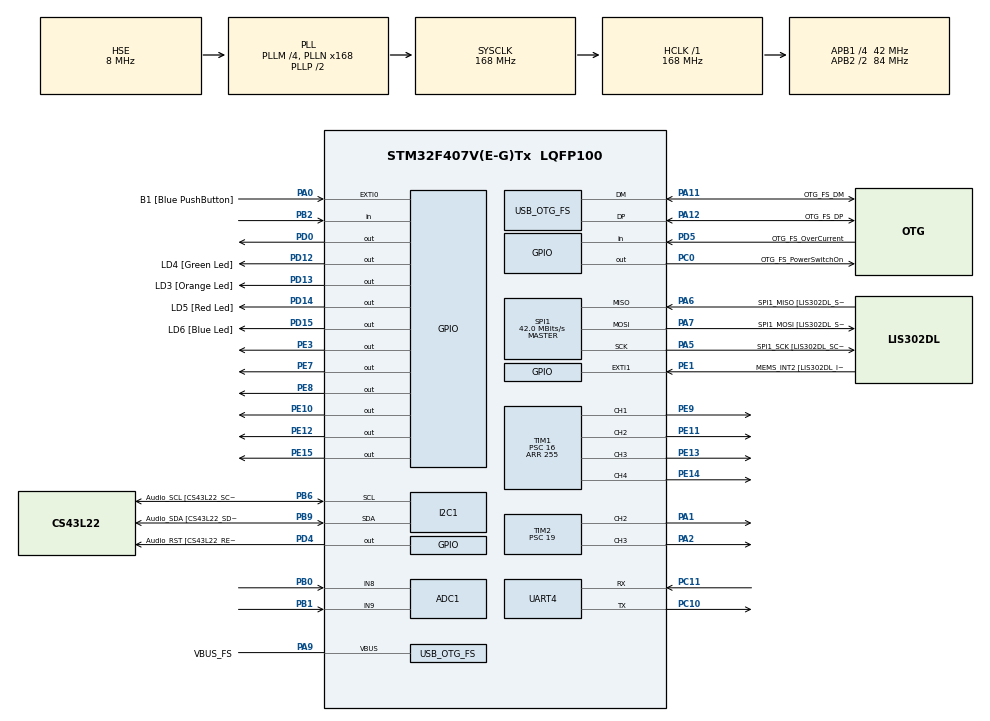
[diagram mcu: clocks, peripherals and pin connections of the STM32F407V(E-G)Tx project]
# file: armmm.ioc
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ADC1.Channel-0\#ChannelRegularConversion=ADC_CHANNEL_8
ADC1.Channel-1\#ChannelRegularConversion=ADC_CHANNEL_9
ADC1.ContinuousConvMode=ENABLE
ADC1.DMAContinuousRequests=ENABLE
ADC1.NbrOfConversion=2
ADC1.NbrOfConversionFlag=1
ADC1.Rank-0\#ChannelRegularConversion=1
ADC1.Rank-1\#ChannelRegularConversion=2
ADC1.SamplingTime-0\#ChannelRegularConversion=ADC_SAMPLETIME_3CYCLES
ADC1.SamplingTime-1\#ChannelRegularConversion=ADC_SAMPLETIME_3CYCLES
ADC1.ScanConvMode=ENABLE
ADC1.master=1
Dma.ADC1.1.Direction=DMA_PERIPH_TO_MEMORY
Dma.ADC1.1.FIFOMode=DMA_FIFOMODE_DISABLE
Dma.ADC1.1.Instance=DMA2_Stream0
Dma.ADC1.1.MemDataAlignment=DMA_MDATAALIGN_HALFWORD
Dma.ADC1.1.MemInc=DMA_MINC_ENABLE
Dma.ADC1.1.Mode=DMA_CIRCULAR
Dma.ADC1.1.PeriphDataAlignment=DMA_PDATAALIGN_HALFWORD
Dma.ADC1.1.PeriphInc=DMA_PINC_DISABLE
Dma.ADC1.1.Priority=DMA_PRIORITY_LOW
Dma.Request0=UART4_RX
Dma.Request1=ADC1
Dma.UART4_RX.0.Direction=DMA_PERIPH_TO_MEMORY
Dma.UART4_RX.0.FIFOMode=DMA_FIFOMODE_DISABLE
Dma.UART4_RX.0.Instance=DMA1_Stream2
Dma.UART4_RX.0.MemDataAlignment=DMA_MDATAALIGN_BYTE
Dma.UART4_RX.0.MemInc=DMA_MINC_ENABLE
Dma.UART4_RX.0.Mode=DMA_CIRCULAR
Dma.UART4_RX.0.PeriphDataAlignment=DMA_PDATAALIGN_BYTE
Dma.UART4_RX.0.PeriphInc=DMA_PINC_DISABLE
Dma.UART4_RX.0.Priority=DMA_PRIORITY_HIGH
FREERTOS.Tasks01=rosTask,24,512,StartRosTask,Default,NULL,Dynamic,NULL,NULL;pidTask,40,512,StartPidTask,Default,NULL,Dynamic,NULL,NULL
FREERTOS.configUSE_NEWLIB_REENTRANT=1
I2C1.I2C_Mode=I2C_Fast
Mcu.Family=STM32F4
Mcu.Name=STM32F407V(E-G)Tx
Mcu.Package=LQFP100
NVIC.DMA1_Stream2_IRQn=true\:5\:0\:false\:false\:true\:true\:false\:true\:true
NVIC.DMA2_Stream0_IRQn=true\:5\:0\:false\:false\:true\:true\:false\:true\:true
NVIC.OTG_FS_IRQn=true\:5\:0\:false\:false\:true\:true\:true\:true\:true
NVIC.PriorityGroup=NVIC_PRIORITYGROUP_4
NVIC.TIM6_DAC_IRQn=true\:15\:0\:false\:false\:true\:false\:false\:true\:true
NVIC.TimeBase=TIM6_DAC_IRQn
NVIC.TimeBaseIP=TIM6
NVIC.UART4_IRQn=true\:5\:0\:false\:false\:true\:true\:true\:true\:true
PA0-WKUP.GPIO_Label=B1 [Blue PushButton]
PA0-WKUP.GPIO_ModeDefaultEXTI=GPIO_MODE_EVT_RISING
PA0-WKUP.GPIO_PuPd=GPIO_NOPULL
PA0-WKUP.Signal=GPXTI0
PA1.Signal=S_TIM2_CH2
PA10.GPIO_Label=OTG_FS_ID
PA10.GPIO_Mode=GPIO_MODE_AF_PP
PA10.GPIO_PuPd=GPIO_NOPULL
PA10.GPIO_Speed=GPIO_SPEED_FREQ_LOW
PA10.Signal=USB_OTG_FS_ID
PA11.GPIO_Label=OTG_FS_DM
PA11.GPIO_Mode=GPIO_MODE_AF_PP
PA11.GPIO_PuPd=GPIO_NOPULL
PA11.GPIO_Speed=GPIO_SPEED_FREQ_LOW
PA11.Mode=Device_Only
PA11.Signal=USB_OTG_FS_DM
PA12.GPIO_Label=OTG_FS_DP
PA12.GPIO_Mode=GPIO_MODE_AF_PP
PA12.GPIO_PuPd=GPIO_NOPULL
PA12.GPIO_Speed=GPIO_SPEED_FREQ_LOW
PA12.Mode=Device_Only
PA12.Signal=USB_OTG_FS_DP
PA13.GPIO_Label=SWDIO
PA13.Mode=Serial_Wire
PA13.Signal=SYS_JTMS-SWDIO
PA14.GPIO_Label=SWCLK
PA14.Mode=Serial_Wire
PA14.Signal=SYS_JTCK-SWCLK
PA2.Signal=S_TIM2_CH3
PA4.GPIO_Label=I2S3_WS [CS43L22_LRCK]
PA4.GPIO_Mode=GPIO_MODE_AF_PP
PA4.GPIO_PuPd=GPIO_NOPULL
PA4.GPIO_Speed=GPIO_SPEED_FREQ_LOW
PA4.Signal=I2S3_WS
PA5.GPIO_Label=SPI1_SCK [LIS302DL_SCL/SPC]
PA5.GPIO_Mode=GPIO_MODE_AF_PP
PA5.GPIO_PuPd=GPIO_NOPULL
PA5.GPIO_Speed=GPIO_SPEED_FREQ_LOW
PA5.Mode=Full_Duplex_Master
PA5.Signal=SPI1_SCK
PA6.GPIO_Label=SPI1_MISO [LIS302DL_SDO]
PA6.GPIO_Mode=GPIO_MODE_AF_PP
PA6.GPIO_PuPd=GPIO_NOPULL
PA6.GPIO_Speed=GPIO_SPEED_FREQ_LOW
PA6.Mode=Full_Duplex_Master
PA6.Signal=SPI1_MISO
PA7.GPIO_Label=SPI1_MOSI [LIS302DL_SDA/SDI/SDO]
PA7.GPIO_Mode=GPIO_MODE_AF_PP
PA7.GPIO_PuPd=GPIO_NOPULL
PA7.GPIO_Speed=GPIO_SPEED_FREQ_LOW
PA7.Mode=Full_Duplex_Master
PA7.Signal=SPI1_MOSI
PA9.GPIO_Label=VBUS_FS
PA9.GPIO_Mode=GPIO_MODE_INPUT
PA9.GPIO_PuPd=GPIO_NOPULL
PA9.Mode=Activate_VBUS
PA9.Signal=USB_OTG_FS_VBUS
PB0.Signal=ADCx_IN8
PB1.Signal=ADCx_IN9
PB10.GPIO_Label=CLK_IN [MP45DT02_CLK]
PB10.GPIO_Mode=GPIO_MODE_AF_PP
PB10.GPIO_PuPd=GPIO_NOPULL
PB10.GPIO_Speed=GPIO_SPEED_FREQ_LOW
PB10.Signal=I2S2_CK
PB2.Signal=GPIO_Input
PB3.GPIO_Label=SWO
PB3.Signal=SYS_JTDO-SWO
PB6.GPIO_Label=Audio_SCL [CS43L22_SCL]
PB6.GPIO_Mode=GPIO_MODE_AF_OD
PB6.GPIO_Pu=GPIO_PULLUP
PB6.GPIO_PuPd=GPIO_NOPULL
PB6.GPIO_Speed=GPIO_SPEED_FREQ_LOW
PB6.Mode=I2C
PB6.Signal=I2C1_SCL
PB9.GPIO_Label=Audio_SDA [CS43L22_SDA]
PB9.GPIO_Mode=GPIO_MODE_AF_OD
PB9.GPIO_Pu=GPIO_PULLUP
PB9.GPIO_PuPd=GPIO_NOPULL
PB9.GPIO_Speed=GPIO_SPEED_FREQ_LOW
PB9.Mode=I2C
PB9.Signal=I2C1_SDA
PC0.GPIO_Label=OTG_FS_PowerSwitchOn
PC0.GPIO_PuPd=GPIO_NOPULL
PC0.GPIO_Speed=GPIO_SPEED_FREQ_LOW
PC0.PinState=GPIO_PIN_SET
PC0.Signal=GPIO_Output
PC10.Mode=Asynchronous
PC10.Signal=UART4_TX
PC11.Mode=Asynchronous
PC11.Signal=UART4_RX
PC14-OSC32_IN.GPIO_Label=PC14-OSC32_IN
PC14-OSC32_IN.Mode=LSE-External-Oscillator
PC14-OSC32_IN.Signal=RCC_OSC32_IN
PC15-OSC32_OUT.GPIO_Label=PC15-OSC32_OUT
PC15-OSC32_OUT.Mode=LSE-External-Oscillator
PC15-OSC32_OUT.Signal=RCC_OSC32_OUT
PC3.GPIO_Label=PDM_OUT [MP45DT02_DOUT]
PC3.GPIO_Mode=GPIO_MODE_AF_PP
PC3.GPIO_PuPd=GPIO_NOPULL
PC3.GPIO_Speed=GPIO_SPEED_FREQ_LOW
PC3.Signal=I2S2_SD
PC7.GPIO_Label=I2S3_MCK [CS43L22_MCLK]
PC7.GPIO_Mode=GPIO_MODE_AF_PP
PC7.GPIO_PuPd=GPIO_NOPULL
PC7.GPIO_Speed=GPIO_SPEED_FREQ_LOW
PC7.Signal=I2S3_MCK
PD0.Signal=GPIO_Output
PD12.GPIO_Label=LD4 [Green Led]
PD12.GPIO_PuPd=GPIO_NOPULL
PD12.GPIO_Speed=GPIO_SPEED_FREQ_LOW
PD12.Signal=GPIO_Output
PD13.GPIO_Label=LD3 [Orange Led]
PD13.GPIO_PuPd=GPIO_NOPULL
PD13.GPIO_Speed=GPIO_SPEED_FREQ_LOW
PD13.Signal=GPIO_Output
PD14.GPIO_Label=LD5 [Red Led]
PD14.GPIO_PuPd=GPIO_NOPULL
PD14.GPIO_Speed=GPIO_SPEED_FREQ_LOW
PD14.Signal=GPIO_Output
PD15.GPIO_Label=LD6 [Blue Led]
PD15.GPIO_PuPd=GPIO_NOPULL
PD15.GPIO_Speed=GPIO_SPEED_FREQ_LOW
PD15.Signal=GPIO_Output
PD4.GPIO_Label=Audio_RST [CS43L22_RESET]
PD4.GPIO_PuPd=GPIO_NOPULL
PD4.GPIO_Speed=GPIO_SPEED_FREQ_LOW
PD4.Signal=GPIO_Output
PD5.GPIO_Label=OTG_FS_OverCurrent
PD5.GPIO_Mode=GPIO_MODE_INPUT
PD5.GPIO_PuPd=GPIO_NOPULL
PD5.Signal=GPIO_Input
PE1.GPIO_Label=MEMS_INT2 [LIS302DL_INT2]
PE1.GPIO_ModeDefaultEXTI=GPIO_MODE_EVT_RISING
PE1.GPIO_PuPd=GPIO_NOPULL
PE1.Signal=GPXTI1
PE10.Signal=GPIO_Output
PE11.Signal=S_TIM1_CH2
PE12.Signal=GPIO_Output
PE13.Signal=S_TIM1_CH3
PE14.Signal=S_TIM1_CH4
PE15.Signal=GPIO_Output
PE3.Signal=GPIO_Output
PE7.Signal=GPIO_Output
PE8.Signal=GPIO_Output
PE9.Signal=S_TIM1_CH1
PH0-OSC_IN.GPIO_Label=PH0-OSC_IN
PH0-OSC_IN.Mode=HSE-External-Oscillator
PH0-OSC_IN.Signal=RCC_OSC_IN
PH1-OSC_OUT.GPIO_Label=PH1-OSC_OUT
PH1-OSC_OUT.Mode=HSE-External-Oscillator
PH1-OSC_OUT.Signal=RCC_OSC_OUT
ProjectManager.HeapSize=0x200
ProjectManager.StackSize=0x400
ProjectManager.TargetToolchain=STM32CubeIDE
RCC.48MHZClocksFreq_Value=48000000
RCC.AHBFreq_Value=168000000
RCC.APB1CLKDivider=RCC_HCLK_DIV4
RCC.APB1Freq_Value=42000000
RCC.APB1TimFreq_Value=84000000
RCC.APB2CLKDivider=RCC_HCLK_DIV2
RCC.APB2Freq_Value=84000000
RCC.APB2TimFreq_Value=168000000
RCC.CortexFreq_Value=168000000
RCC.HCLKFreq_Value=168000000
RCC.HSE_VALUE=8000000
RCC.HSI_VALUE=16000000
RCC.PLLM=4
RCC.PLLN=168
RCC.PLLQ=7
RCC.SYSCLKFreq_VALUE=168000000
RCC.SYSCLKSource=RCC_SYSCLKSOURCE_PLLCLK
RCC.VCOOutputFreq_Value=336000000
SH.ADCx_IN8.0=ADC1_IN8,IN8
SH.ADCx_IN9.0=ADC1_IN9,IN9
SH.S_TIM1_CH1.0=TIM1_CH1,PWM Generation1 CH1
SH.S_TIM1_CH2.0=TIM1_CH2,PWM Generation2 CH2
SH.S_TIM1_CH3.0=TIM1_CH3,PWM Generation3 CH3
SH.S_TIM1_CH4.0=TIM1_CH4,PWM Generation4 CH4
SH.S_TIM2_CH2.0=TIM2_CH2,PWM Generation2 CH2
SH.S_TIM2_CH3.0=TIM2_CH3,PWM Generation3 CH3
SPI1.BaudRatePrescaler-Full_Duplex_Master=SPI_BAUDRATEPRESCALER_2
SPI1.CalculateBaudRate=42.0 MBits/s
SPI1.CalculateBaudRate-Full_Duplex_Master=42.0 MBits/s
SPI1.Direction=SPI_DIRECTION_2LINES
SPI1.Mode=SPI_MODE_MASTER
SPI1.Mode-Full_Duplex_Master=SPI_MODE_MASTER
SPI1.VirtualType=VM_MASTER
TIM1.Channel-PWM\ Generation1\ CH1=TIM_CHANNEL_1
TIM1.Channel-PWM\ Generation2\ CH2=TIM_CHANNEL_2
TIM1.Channel-PWM\ Generation3\ CH3=TIM_CHANNEL_3
TIM1.Channel-PWM\ Generation4\ CH4=TIM_CHANNEL_4
TIM1.Period=255
TIM1.Prescaler=16
TIM2.Channel-PWM\ Generation2\ CH2=TIM_CHANNEL_2
TIM2.Channel-PWM\ Generation3\ CH3=TIM_CHANNEL_3
TIM2.Period=255
TIM2.Prescaler=19
UART4.VirtualMode=Asynchronous
USB_DEVICE.CLASS_NAME_FS=CDC
USB_DEVICE.VirtualMode-CDC_FS=Cdc
USB_DEVICE.VirtualModeFS=Cdc_FS
USB_OTG_FS.VirtualMode=Device_Only
VP_FREERTOS_VS_CMSIS_V2.Mode=CMSIS_V2
VP_SYS_VS_tim6.Mode=TIM6
VP_TIM1_VS_ClockSourceINT.Mode=Internal
VP_TIM2_VS_ClockSourceINT.Mode=Internal
VP_USB_DEVICE_VS_USB_DEVICE_CDC_FS.Mode=CDC_FS
board=STM32F407G-DISC1

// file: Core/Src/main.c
/* USER CODE BEGIN Header */
/**
  ******************************************************************************
  * @file           : main.c
  * @brief          : Main program body
  ******************************************************************************
  * @attention
  *
  * Copyright (c) 2026 STMicroelectronics.
  * All rights reserved.
  *
  * This software is licensed under terms that can be found in the LICENSE file
  * in the root directory of this software component.
  * If no LICENSE file comes with this software, it is provided AS-IS.
  *
  ******************************************************************************
  */
/* USER CODE END Header */
#include "main.h"
#include "cmsis_os.h"
#include "adc.h"
#include "dma.h"
#include "i2c.h"
#include "spi.h"
#include "tim.h"
#include "usart.h"
#include "usb_device.h"
#include "gpio.h"

void SystemClock_Config(void);
void MX_FREERTOS_Init(void);

int main(void)
{

  /* MCU Configuration--------------------------------------------------------*/

  /* Reset of all peripherals, Initializes the Flash interface and the Systick. */
  HAL_Init();

  /* Configure the system clock */
  SystemClock_Config();

  /* Initialize all configured peripherals */
  MX_GPIO_Init();
  MX_DMA_Init();
  MX_I2C1_Init();
  MX_SPI1_Init();
  MX_TIM1_Init();
  MX_TIM2_Init();
  MX_UART4_Init();
  MX_ADC1_Init();

  /* Init scheduler */
  osKernelInitialize();  /* Call init function for freertos objects (in cmsis_os2.c) */
  MX_FREERTOS_Init();

  /* Start scheduler */
  osKernelStart();

  /* We should never get here as control is now taken by the scheduler */

  /* Infinite loop */
  while (1)
  {

  }
}

void SystemClock_Config(void)
{
  RCC_OscInitTypeDef RCC_OscInitStruct = {0};
  RCC_ClkInitTypeDef RCC_ClkInitStruct = {0};

  /** Configure the main internal regulator output voltage
  */
  __HAL_RCC_PWR_CLK_ENABLE();
  __HAL_PWR_VOLTAGESCALING_CONFIG(PWR_REGULATOR_VOLTAGE_SCALE1);

  /** Initializes the RCC Oscillators according to the specified parameters
  * in the RCC_OscInitTypeDef structure.
  */
  RCC_OscInitStruct.OscillatorType = RCC_OSCILLATORTYPE_HSE;
  RCC_OscInitStruct.HSEState = RCC_HSE_ON;
  RCC_OscInitStruct.PLL.PLLState = RCC_PLL_ON;
  RCC_OscInitStruct.PLL.PLLSource = RCC_PLLSOURCE_HSE;
  RCC_OscInitStruct.PLL.PLLM = 4;
  RCC_OscInitStruct.PLL.PLLN = 168;
  RCC_OscInitStruct.PLL.PLLP = RCC_PLLP_DIV2;
  RCC_OscInitStruct.PLL.PLLQ = 7;
  if (HAL_RCC_OscConfig(&RCC_OscInitStruct) != HAL_OK)
  {
    Error_Handler();
  }

  /** Initializes the CPU, AHB and APB buses clocks
  */
  RCC_ClkInitStruct.ClockType = RCC_CLOCKTYPE_HCLK|RCC_CLOCKTYPE_SYSCLK
                              |RCC_CLOCKTYPE_PCLK1|RCC_CLOCKTYPE_PCLK2;
  RCC_ClkInitStruct.SYSCLKSource = RCC_SYSCLKSOURCE_PLLCLK;
  RCC_ClkInitStruct.AHBCLKDivider = RCC_SYSCLK_DIV1;
  RCC_ClkInitStruct.APB1CLKDivider = RCC_HCLK_DIV4;
  RCC_ClkInitStruct.APB2CLKDivider = RCC_HCLK_DIV2;

  if (HAL_RCC_ClockConfig(&RCC_ClkInitStruct, FLASH_LATENCY_5) != HAL_OK)
  {
    Error_Handler();
  }
}

void HAL_TIM_PeriodElapsedCallback(TIM_HandleTypeDef *htim)
{
  if (htim->Instance == TIM6)
  {
    HAL_IncTick();
  }
}

void Error_Handler(void)
{
  __disable_irq();
  while (1)
  {
  }
}

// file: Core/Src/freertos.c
/* USER CODE BEGIN Header */
/**
  ******************************************************************************
  * File Name          : freertos.c
  * Description        : Code for freertos applications
  ******************************************************************************
  * @attention
  *
  * Copyright (c) 2026 STMicroelectronics.
  * All rights reserved.
  *
  * This software is licensed under terms that can be found in the LICENSE file
  * in the root directory of this software component.
  * If no LICENSE file comes with this software, it is provided AS-IS.
  *
  ******************************************************************************
  */
/* USER CODE END Header */

#include "FreeRTOS.h"
#include "task.h"
#include "main.h"
#include "cmsis_os.h"

/* USER CODE BEGIN Includes */
#include "RobotCore.h"
/* USER CODE END Includes */

/* Definitions for rosTask */
osThreadId_t rosTaskHandle;
const osThreadAttr_t rosTask_attributes = {
  .name = "rosTask",
  .stack_size = 512 * 4,
  .priority = (osPriority_t) osPriorityNormal,
};
/* Definitions for pidTask */
osThreadId_t pidTaskHandle;
const osThreadAttr_t pidTask_attributes = {
  .name = "pidTask",
  .stack_size = 512 * 4,
  .priority = (osPriority_t) osPriorityHigh,
};

void StartRosTask(void *argument);
void StartPidTask(void *argument);

extern void MX_USB_DEVICE_Init(void);
void MX_FREERTOS_Init(void); /* (MISRA C 2004 rule 8.1) */

void MX_FREERTOS_Init(void) {

  /* Create the thread(s) */
  /* creation of rosTask */
  rosTaskHandle = osThreadNew(StartRosTask, NULL, &rosTask_attributes);

  /* creation of pidTask */
  pidTaskHandle = osThreadNew(StartPidTask, NULL, &pidTask_attributes);

}

void StartRosTask(void *argument)
{
  /* init code for USB_DEVICE */
  MX_USB_DEVICE_Init();
  /* USER CODE BEGIN StartRosTask */
  RobotCore_Init();
  /* Infinite loop */
  for(;;)
  {
    RobotCore_ROSTask();
    osDelay(1);
  }
  /* USER CODE END StartRosTask */
}

void StartPidTask(void *argument)
{
  /* USER CODE BEGIN StartPidTask */
  /* Infinite loop */
  for(;;)
  {
    RobotCore_PIDTask();
    osDelay(20);  /* 50Hz PID loop (dt = 0.02s) */
  }
  /* USER CODE END StartPidTask */
}
